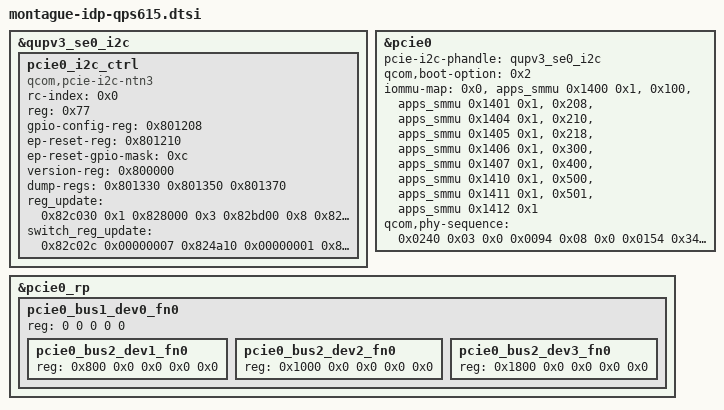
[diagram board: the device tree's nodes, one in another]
#include "montague-hsp.dtsi"

&qupv3_se0_i2c {
	status = "ok";

	pcie0_i2c_ctrl: pcie0_i2c_ctrl {
		compatible = "qcom,pcie-i2c-ntn3";
		rc-index = <0x0>;
		reg = <0x77>;
		gpio-config-reg = <0x801208>;
		ep-reset-reg = <0x801210>;
		ep-reset-gpio-mask = <0xc>;
		version-reg = <0x800000>;
		dump-regs = <0x801330 0x801350 0x801370>;
		reg_update = <0x82c030 0x1
					0x828000 0x3
					0x82bd00 0x8
					0x82c030 0x2
					0x828000 0x3
					0x82bd00 0x8
					0x82c030 0x8
					0x828000 0x1
					0x82bd00 0x8
					0x82c01c 0x10
					0x82c030 0xf
					0x828000 0xf
					0x82b268 0x2>;
		/*FOM for preset caluclation*/
		switch_reg_update = <0x82c02c 0x00000007
					0x824a10 0x00000001
					0x82c030 0x00000008
					0x828000 0x00000001
					0x82b074 0x00000020
					0x82b2bc 0x00000001>;
	};
};

&pcie0 {

	pcie-i2c-phandle = <&qupv3_se0_i2c>;
	qcom,boot-option = <0x2>;
	iommu-map = <0x0 &apps_smmu 0x1400 0x1>,
		<0x100 &apps_smmu 0x1401 0x1>,
		<0x208 &apps_smmu 0x1404 0x1>,
		<0x210 &apps_smmu 0x1405 0x1>,
		<0x218 &apps_smmu 0x1406 0x1>,
		<0x300 &apps_smmu 0x1407 0x1>,
		<0x400 &apps_smmu 0x1410 0x1>,
		<0x500 &apps_smmu 0x1411 0x1>,
		<0x501 &apps_smmu 0x1412 0x1>;

	qcom,phy-sequence = <0x0240 0x03 0x0
			0x0094 0x08 0x0
			0x0154 0x34 0x0
			0x016c 0x08 0x0
			0x0058 0x0f 0x0
			0x00a4 0x42 0x0
			0x0110 0x24 0x0
			0x011c 0x03 0x0
			0x0118 0xb4 0x0
			0x010c 0x02 0x0
			0x01bc 0x11 0x0
			0x00bc 0x82 0x0
			0x00d4 0x03 0x0
			0x00d0 0x55 0x0
			0x00cc 0x55 0x0
			0x00b0 0x1a 0x0
			0x00ac 0x0a 0x0
			0x00c4 0x68 0x0
			0x00e0 0x02 0x0
			0x00dc 0xaa 0x0
			0x00d8 0xab 0x0
			0x00b8 0x34 0x0
			0x00b4 0x14 0x0
			0x0158 0x01 0x0
			0x0074 0x06 0x0
			0x007c 0x16 0x0
			0x0084 0x36 0x0
			0x0078 0x06 0x0
			0x0080 0x16 0x0
			0x0088 0x36 0x0
			0x01b0 0x1e 0x0
			0x01ac 0xca 0x0
			0x01b8 0x18 0x0
			0x01b4 0xa2 0x0
			0x0050 0x07 0x0
			0x0010 0x01 0x0
			0x001c 0x31 0x0
			0x0020 0x01 0x0
			0x0024 0xde 0x0
			0x0028 0x07 0x0
			0x0030 0x4c 0x0
			0x0034 0x06 0x0
			0x0ee4 0x20 0x0
			0x0e84 0x75 0x0
			0x0e90 0x3f 0x0
			0x115c 0x7f 0x0
			0x1160 0xff 0x0
			0x1164 0xbf 0x0
			0x1168 0x3f 0x0
			0x116c 0xd8 0x0
			0x1170 0xdc 0x0
			0x1174 0xdc 0x0
			0x1178 0x5c 0x0
			0x117c 0x34 0x0
			0x1180 0xa6 0x0
			0x1190 0x34 0x0
			0x1194 0x38 0x0
			0x10d8 0x0f 0x0
			0x0e3c 0x12 0x0
			0x0e40 0x01 0x0
			0x10dc 0x00 0x0
			0x104c 0x08 0x0
			0x1050 0x08 0x0
			0x1044 0xf0 0x0
			0x11a4 0x38 0x0
			0x10cc 0xf0 0x0
			0x10f4 0x07 0x0
			0x1008 0x09 0x0
			0x1014 0x05 0x0
			0x0694 0x00 0x0
			0x0654 0x00 0x0
			0x06a8 0x0f 0x0
			0x0048 0x90 0x0
			0x0620 0xc1 0x0
			0x0624 0x40 0x0
			0x0388 0x77 0x0
			0x0398 0x0b 0x0
			0x02dc 0x05 0x0
			0x0200 0x00 0x0
			0x0244 0x03 0x0>;

};

&pcie0_rp {
	#address-cells = <5>;
	#size-cells = <0>;

	/* BDF 1.0.0 */
	pcie0_bus1_dev0_fn0: pcie0_bus1_dev0_fn0 {
		reg = <0 0 0 0 0>;

		/* BDF 2.1.0 */
		pcie0_bus2_dev1_fn0: pcie0_bus2_dev1_fn0 {
			reg = <0x800 0x0 0x0 0x0 0x0>;
		};

		/* BDF 2.2.0 */
		pcie0_bus2_dev2_fn0: pcie0_bus2_dev2_fn0 {
			reg = <0x1000 0x0 0x0 0x0 0x0>;
		};

		/* BDF 2.3.0 */
		pcie0_bus2_dev3_fn0: pcie0_bus2_dev3_fn0 {
			reg = <0x1800 0x0 0x0 0x0 0x0>;
		};
	};
};

